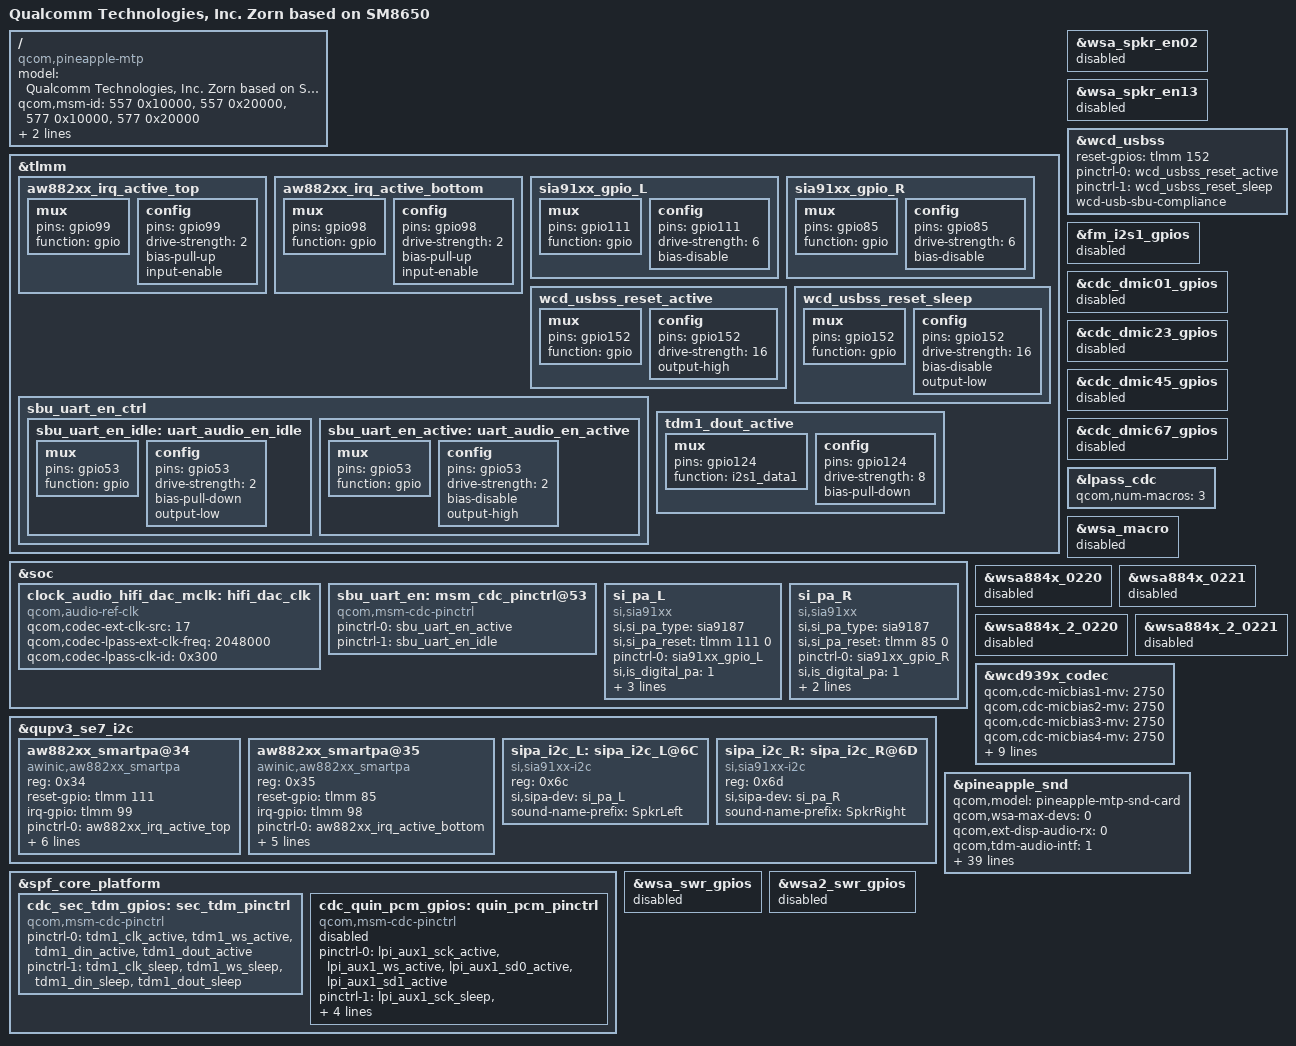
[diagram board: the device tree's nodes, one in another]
/dts-v1/;
/plugin/;

#include "pineapple-audio-mtp.dtsi"

/ {
	model = "Qualcomm Technologies, Inc. Zorn based on SM8650";
	compatible = "qcom,pineapple-mtp", "qcom,pineapple", "qcom,mtp";
	qcom,msm-id = <557 0x10000>, <557 0x20000>, <577 0x10000>, <577 0x20000>;
	qcom,board-id = <8 0>;
	xiaomi,miboard-id = <0xd 0>;
};

&tlmm {
	aw882xx_irq_active_top: aw882xx_irq_active_top {
		mux {
			pins = "gpio99";
			function = "gpio";
		};

		config {
			pins = "gpio99";
			drive-strength = <2>;
			bias-pull-up;
			input-enable;
		};
	};

	aw882xx_irq_active_bottom: aw882xx_irq_active_bottom {
		mux {
			pins = "gpio98";
			function = "gpio";
		};

		config {
			pins = "gpio98";
			drive-strength = <2>;
			bias-pull-up;
			input-enable;
		};
	};

	sia91xx_gpio_L: sia91xx_gpio_L {
		mux {
			pins = "gpio111";
			function = "gpio";
		};

		config {
			pins = "gpio111";
			drive-strength = <6>;
			bias-disable;
		};
	};

	sia91xx_gpio_R: sia91xx_gpio_R {
		mux {
			pins = "gpio85";
			function = "gpio";
		};

		config {
			pins = "gpio85";
			drive-strength = <6>;
			bias-disable;
		};
	};

	wcd_usbss_reset_active: wcd_usbss_reset_active {
		mux {
			pins = "gpio152";
			function = "gpio";
		};

		config {
			pins = "gpio152";
			drive-strength = <16>;
			output-high;
		};
	};

	wcd_usbss_reset_sleep: wcd_usbss_reset_sleep {
		mux {
			pins = "gpio152";
			function = "gpio";
		};

		config {
			pins = "gpio152";
			drive-strength = <16>;
			bias-disable;
			output-low;
		};
	};

	sbu_uart_en_ctrl {
		sbu_uart_en_idle: uart_audio_en_idle {
			mux {
				pins = "gpio53";
				function = "gpio";
			};

			config {
				pins = "gpio53";
				drive-strength = <2>;
				bias-pull-down;
				output-low;
			};
		};

		sbu_uart_en_active: uart_audio_en_active {
			mux {
				pins = "gpio53";
				function = "gpio";
			};

			config {
				pins = "gpio53";
				drive-strength = <2>;
				bias-disable;
				output-high;
			};
		};
	};

	tdm1_dout_active: tdm1_dout_active {
		mux {
			pins = "gpio124";
			function = "i2s1_data1";
		};

		config {
			pins = "gpio124";
			drive-strength = <8>;
			bias-pull-down;
		};
	};
};

&soc {
	clock_audio_hifi_dac_mclk: hifi_dac_clk {
		compatible = "qcom,audio-ref-clk";
		qcom,codec-ext-clk-src = <17>;
		qcom,codec-lpass-ext-clk-freq = <2048000>;
		qcom,codec-lpass-clk-id = <0x300>;
		#clock-cells = <1>;
	};

	sbu_uart_en: msm_cdc_pinctrl@53 {
		compatible = "qcom,msm-cdc-pinctrl";
		pinctrl-names = "aud_active", "aud_sleep";
		pinctrl-0 = <&sbu_uart_en_active>;
		pinctrl-1 = <&sbu_uart_en_idle>;
		#gpio-cells = <0>;
	};

	si_pa_L: si_pa_L {
		compatible = "si,sia91xx";
		si,si_pa_type = "sia9187";
		si,si_pa_reset = <&tlmm 111 0>;
		pinctrl-names = "si_pa_gpio";
		pinctrl-0 = <&sia91xx_gpio_L>;
		si,is_digital_pa = <1>;
		si,si_pa_disable_pin = <0>;
		channel_num = <0>;
		spksw-gpio = <&tlmm 70 0>;
	};

	si_pa_R: si_pa_R {
		compatible = "si,sia91xx";
		si,si_pa_type = "sia9187";
		si,si_pa_reset = <&tlmm 85 0>;
		pinctrl-names = "si_pa_gpio";
		pinctrl-0 = <&sia91xx_gpio_R>;
		si,is_digital_pa = <1>;
		si,si_pa_disable_pin = <0>;
		channel_num = <1>;
	};
};

&wsa_spkr_en02 {
	status = "disabled";
};

&wsa_spkr_en13 {
	status = "disabled";
};

&qupv3_se7_i2c {
	status = "ok";

	aw882xx_smartpa@34 {
		compatible = "awinic,aw882xx_smartpa";
		reg = <0x34>;
		reset-gpio = <&tlmm 111 0>;
		irq-gpio = <&tlmm 99 0x2008>;
		pinctrl-names = "default";
		pinctrl-0 = <&aw882xx_irq_active_top>;
		dc-flag = <0>;
		sound-channel = <0>;
		aw-re-min = <4000>;
		aw-re-max = <30000>;
		aw-cali-mode = "aw_none ";
		spksw-gpio = <&tlmm 70 0>;
		status = "okay";
	};

	aw882xx_smartpa@35 {
		compatible = "awinic,aw882xx_smartpa";
		reg = <0x35>;
		reset-gpio = <&tlmm 85 0>;
		irq-gpio = <&tlmm 98 0x2008>;
		pinctrl-names = "default";
		pinctrl-0 = <&aw882xx_irq_active_bottom>;
		dc-flag = <0>;
		sound-channel = <1>;
		aw-re-min = <4000>;
		aw-re-max = <30000>;
		aw-cali-mode = "aw_none ";
		status = "okay";
	};

	sipa_i2c_L: sipa_i2c_L@6C {
		compatible = "si,sia91xx-i2c";
		reg = <0x6c>;
		si,sipa-dev = <&si_pa_L>;
		sound-name-prefix = "SpkrLeft";
	};

	sipa_i2c_R: sipa_i2c_R@6D {
		compatible = "si,sia91xx-i2c";
		reg = <0x6d>;
		si,sipa-dev = <&si_pa_R>;
		sound-name-prefix = "SpkrRight";
	};
};

&wcd_usbss {
	reset-gpios = <&tlmm 152 0>;
	pinctrl-names = "usbss_active", "usbss_sleep";
	pinctrl-0 = <&wcd_usbss_reset_active>;
	pinctrl-1 = <&wcd_usbss_reset_sleep>;
	wcd-usb-sbu-compliance;
};

&spf_core_platform {
	cdc_sec_tdm_gpios: sec_tdm_pinctrl {
		compatible = "qcom,msm-cdc-pinctrl";
		pinctrl-names = "aud_active", "aud_sleep";
		pinctrl-0 = <&tdm1_clk_active &tdm1_ws_active
				&tdm1_din_active &tdm1_dout_active>;
		pinctrl-1 = <&tdm1_clk_sleep &tdm1_ws_sleep
				&tdm1_din_sleep &tdm1_dout_sleep>;
		#gpio-cells = <0>;
		status = "ok";
	};

	cdc_quin_pcm_gpios: quin_pcm_pinctrl {
		compatible = "qcom,msm-cdc-pinctrl";
		pinctrl-names = "aud_active", "aud_sleep";
		pinctrl-0 = <&lpi_aux1_sck_active &lpi_aux1_ws_active
				&lpi_aux1_sd0_active &lpi_aux1_sd1_active>;
		pinctrl-1 = <&lpi_aux1_sck_sleep &lpi_aux1_ws_sleep
				&lpi_aux1_sd0_sleep &lpi_aux1_sd1_sleep>;
		qcom,tlmm-pins = <171 172 174>;
		qcom,lpi-gpios;
		#gpio-cells = <0>;
		status = "disabled";
	};
};

&fm_i2s1_gpios {
	status = "disabled";
};

&cdc_dmic01_gpios {
	status = "disabled";
};

&cdc_dmic23_gpios {
	status = "disabled";
};

&cdc_dmic45_gpios {
	status = "disabled";
};

&cdc_dmic67_gpios {
	status = "disabled";
};

&lpass_cdc {
	qcom,num-macros = <3>;
};

&wsa_macro {
	status = "disabled";
};

&wsa884x_0220 {
	status = "disabled";
};

&wsa884x_0221 {
	status = "disabled";
};

&wsa884x_2_0220 {
	status = "disabled";
};

&wsa884x_2_0221 {
	status = "disabled";
};

&wcd939x_codec {
	qcom,cdc-micbias1-mv = <2750>;
	qcom,cdc-micbias2-mv = <2750>;
	qcom,cdc-micbias3-mv = <2750>;
	qcom,cdc-micbias4-mv = <2750>;
	qcom,usbcss-hs-xtalk-config = <0>;
	qcom,usbcss-hs-rdson = <345>;
	qcom,usbcss-hs-r2 = <3715>;
	qcom,usbcss-hs-r3 = <91>;
	qcom,usbcss-hs-r4 = <744>;
	qcom,usbcss-hs-r6 = <72>;
	qcom,usbcss-hs-r7 = <71>;
	qcom,usbcss-hs-lin-k-aud = <13>;
	qcom,usbcss-hs-lin-k-gnd = <13>;
};

&pineapple_snd {
	qcom,model = "pineapple-mtp-snd-card";
	qcom,wsa-max-devs = <0>;
	qcom,ext-disp-audio-rx = <0>;
	qcom,tdm-audio-intf = <1>;
	qcom,tdm-max-slots = <4>;
	qcom,tdm-clk-attribute = <4>, <4>, <4>, <4>, <4>, <4>, <4>, <4>;
	qcom,sec-mi2s-gpios = <&cdc_sec_tdm_gpios>;
	qcom,uart-audio-sw-gpio = <&sbu_uart_en>;
	qcom,wcd-disable-legacy-surge;
	qcom,msm-mbhc-usbc-audio-supported = <1>;
	qcom,msm-mbhc-hphl-swh = <0>;
	qcom,msm-mbhc-gnd-swh = <0>;
	qcom,audio-routing =
		"AMIC1", "Analog Mic1",
		"AMIC1", "MIC BIAS1",
		"AMIC2", "Analog Mic2",
		"AMIC2", "MIC BIAS2",
		"AMIC3", "Analog Mic3",
		"AMIC3", "MIC BIAS3",
		"AMIC4", "Analog Mic4",
		"AMIC4", "MIC BIAS4",
		"AMIC5", "Analog Mic5",
		"AMIC5", "MIC BIAS4",
		"VA AMIC1", "Analog Mic1",
		"VA AMIC1", "VA MIC BIAS1",
		"VA AMIC2", "Analog Mic2",
		"VA AMIC2", "VA MIC BIAS2",
		"VA AMIC3", "Analog Mic3",
		"VA AMIC3", "VA MIC BIAS3",
		"VA AMIC4", "Analog Mic4",
		"VA AMIC4", "VA MIC BIAS3",
		"VA AMIC5", "Analog Mic5",
		"VA AMIC5", "VA MIC BIAS4",
		"TX DMIC0", "Digital Mic0",
		"Digital Mic0", "MIC BIAS3",
		"TX DMIC1", "Digital Mic1",
		"Digital Mic1", "MIC BIAS3",
		"TX DMIC2", "Digital Mic2",
		"Digital Mic2", "MIC BIAS1",
		"TX DMIC3", "Digital Mic3",
		"Digital Mic3", "MIC BIAS1",
		"IN1_HPHL", "HPHL_OUT",
		"IN2_HPHR", "HPHR_OUT",
		"IN3_EAR", "AUX_OUT",
		"HAP_IN", "PCM_OUT",
		"RX_TX DEC0_INP", "TX DEC0 MUX",
		"RX_TX DEC1_INP", "TX DEC1 MUX",
		"RX_TX DEC2_INP", "TX DEC2 MUX",
		"RX_TX DEC3_INP", "TX DEC3 MUX",
		"TX SWR_INPUT", "WCD_TX_OUTPUT",
		"VA SWR_INPUT", "VA_SWR_CLK",
		"VA SWR_INPUT", "WCD_TX_OUTPUT",
		"VA_AIF1 CAP", "VA_SWR_CLK",
		"VA_AIF2 CAP", "VA_SWR_CLK",
		"VA_AIF3 CAP", "VA_SWR_CLK",
		"VA DMIC0", "Digital Mic0",
		"VA DMIC1", "Digital Mic1",
		"VA DMIC2", "Digital Mic2",
		"VA DMIC3", "Digital Mic3",
		"Digital Mic0", "VA MIC BIAS3",
		"Digital Mic1", "VA MIC BIAS3",
		"Digital Mic2", "VA MIC BIAS1",
		"Digital Mic3", "VA MIC BIAS1";
};

&wsa_swr_gpios {
	status = "disabled";
};

&wsa2_swr_gpios {
	status = "disabled";
};
